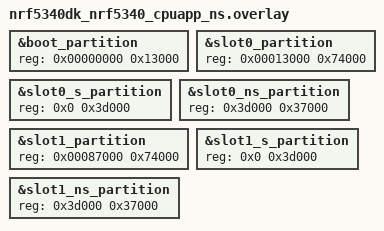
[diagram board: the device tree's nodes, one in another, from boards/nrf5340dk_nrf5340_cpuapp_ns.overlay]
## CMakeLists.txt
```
# SPDX-License-Identifier: Apache-2.0

cmake_minimum_required(VERSION 3.20.0)

find_package(Zephyr REQUIRED HINTS $ENV{ZEPHYR_BASE})
project(devacademy)

# STEP 6.1 - Include common files from Zephyr USB samples
target_sources(app PRIVATE src/main.c)
```

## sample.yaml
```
sample:
  description: nRF Connect SDK Intermediate Course by Nordic Developer Academy (https://academy.nordicsemi.com/)
  name: nRF Connect SDK Intermediate Course - Lesson 9 Exercise 4
  
common: 
    sysbuild: true
    build_only: true
    skip: true
    integration_platforms: 
      - nrf52833dk/nrf52833
      - nrf52840dk/nrf52840
      - nrf5340dk/nrf5340/cpuapp
      - nrf54lm20dk/nrf54lm20a/cpuapp
    platform_allow:
      - nrf52833dk/nrf52833
      - nrf52840dk/nrf52840
      - nrf5340dk/nrf5340/cpuapp
      - nrf54lm20dk/nrf54lm20a/cpuapp
    
tests:
  ncs_inter.l9.e4: {}
```

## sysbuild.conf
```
# Add MCUboot
SB_CONFIG_BOOTLOADER_MCUBOOT=y
SB_CONFIG_MCUBOOT_USE_ALL_AVAILABLE_RAM=y
```

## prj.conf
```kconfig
CONFIG_GPIO=y

# Enable MCUboot
CONFIG_BOOTLOADER_MCUBOOT=y

# Enable mcumgr DFU in application
CONFIG_MCUMGR=y

# Enable MCUMGR management for both OS and Images
CONFIG_MCUMGR_GRP_OS=y
CONFIG_MCUMGR_GRP_IMG=y

# Configure MCUMGR transport to UART
CONFIG_MCUMGR_TRANSPORT_UART=y

# Dependencies
# Configure dependencies for CONFIG_MCUMGR  
CONFIG_NET_BUF=y
CONFIG_ZCBOR=y
CONFIG_CRC=y

# Configure dependencies for CONFIG_MCUMGR_GRP_IMG  
CONFIG_FLASH=y
CONFIG_IMG_MANAGER=y

# Configure dependencies for CONFIG_IMG_MANAGER  
CONFIG_STREAM_FLASH=y
CONFIG_FLASH_MAP=y

# Configure dependencies for CONFIG_MCUMGR_TRANSPORT_UART 
CONFIG_BASE64=y

# STEP 5.3 - Enable USB subsystem
```

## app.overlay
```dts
/* STEP 5.1 - choose CDC ACM for mcumgr */

/* STEP 5.2 - Configure CDC ACM */
```

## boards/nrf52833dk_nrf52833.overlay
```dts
/delete-node/ &slot1_partition;
/delete-node/ &slot0_partition;
/delete-node/ &storage_partition;

&flash0 {
	partitions {
		ranges;
		#address-cells = <1>;
		#size-cells = <1>;

		boot_partition: partition@0 {
			compatible = "zephyr,mapped-partition";
			label = "mcuboot";
			reg = <0x00000000 0x13000>;
		};

		slot0_partition: partition@13000 {
			compatible = "zephyr,mapped-partition";
			label = "image-0";
			reg = <0x00013000 0x17000>;
		};

		slot1_partition: partition@2a000 {
			compatible = "zephyr,mapped-partition";
			label = "image-1";
			reg = <0x0002a000 0x17000>;
		};

		storage_partition: partition@41000 {
			compatible = "zephyr,mapped-partition";
			label = "storage";
			reg = <0x00041000 0x00006000>;
		};
	};
};

/* STEP 5.1 - Configure CDC ACM */
/* STEP 5.2 - Choose CDC ACM for mcumgr */
```

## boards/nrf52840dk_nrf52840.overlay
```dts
/delete-node/ &slot1_partition;
/delete-node/ &slot0_partition;
/delete-node/ &storage_partition;

&flash0 {
	partitions {
		ranges;
		#address-cells = <1>;
		#size-cells = <1>;

		boot_partition: partition@0 {
			compatible = "zephyr,mapped-partition";
			label = "mcuboot";
			reg = <0x00000000 0x00013000>;
		};

		slot0_partition: partition@13000 {
			compatible = "zephyr,mapped-partition";
			label = "image-0";
			reg = <0x00013000 0x00076000>;
		};

		slot1_partition: partition@89000 {
			compatible = "zephyr,mapped-partition";
			label = "image-1";
			reg = <0x00089000 0x00076000>;
		};

		/*
		 * The flash starting at 0x000f8000 and ending at
		 * 0x000fffff is reserved for use by the application.
		 */

		/*
		 * Storage partition will be used by FCB/LittleFS/NVS
		 * if enabled.
		 */
		storage_partition: partition@ff000 {
			compatible = "zephyr,mapped-partition";
			label = "storage";
			reg = <0x000ff000 0x00001000>;
		};
	};
};

/* STEP 5.1 - Configure CDC ACM */
/* STEP 5.2 - Choose CDC ACM for mcumgr */
```

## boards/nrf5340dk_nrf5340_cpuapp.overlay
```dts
/delete-node/ &slot1_partition;
/delete-node/ &slot0_partition;
/delete-node/ &storage_partition;

&flash0 {
	partitions {
		ranges;
		#address-cells = <1>;
		#size-cells = <1>;

		boot_partition: partition@0 {
			compatible = "zephyr,mapped-partition";
			label = "mcuboot";
			reg = <0x00000000 0x13000>;
		};

		slot0_partition: partition@13000 {
			compatible = "zephyr,mapped-partition";
			label = "image-0";
			reg = <0x00013000 0x74000>;
		};

		slot1_partition: partition@87000 {
			compatible = "zephyr,mapped-partition";
			label = "image-1";
			reg = <0x00087000 0x74000>;
		};
	};
};

/* STEP 5.1 - Configure CDC ACM */
/* STEP 5.2 - Choose CDC ACM for mcumgr */
```

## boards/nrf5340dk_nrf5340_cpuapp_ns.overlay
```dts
/delete-node/ &storage_partition;

&boot_partition {
	reg = <0x00000000 0x13000>;
};

&slot0_partition {
	reg = <0x00013000 0x74000>;
	ranges = <0x0 0x13000 0x74000>;
};

&slot0_s_partition {
	reg = <0x0 0x3d000>;
};

&slot0_ns_partition {
	reg = <0x3d000 0x37000>;
};

&slot1_partition {
	reg = <0x00087000 0x74000>;
	ranges = <0x0 0x87000 0x74000>;
};

&slot1_s_partition {
	reg = <0x0 0x3d000>;
};

&slot1_ns_partition {
	reg = <0x3d000 0x37000>;
};

/* STEP 5.1 - Configure CDC ACM */
/* STEP 5.2 - Choose CDC ACM for mcumgr */
```

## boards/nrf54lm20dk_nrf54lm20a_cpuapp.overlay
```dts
/delete-node/ &boot_partition;
/delete-node/ &slot0_partition;
/delete-node/ &slot1_partition;

&cpuapp_rram {
    partitions {
        boot_partition: partition@0 {
            compatible = "zephyr,mapped-partition";
            label = "mcuboot";
            reg = <0x0 DT_SIZE_K(100)>;
        };

        slot0_partition: partition@19000 {
            compatible = "zephyr,mapped-partition";
            label = "image-0";
            reg = <0x19000 DT_SIZE_K(800)>;
        };

        slot1_partition: partition@e1000 {
            compatible = "zephyr,mapped-partition";
            label = "image-1";
            reg = <0xe1000 DT_SIZE_K(800)>;
        };
    };
};
/* STEP 5.1 - Configure CDC ACM */
/* STEP 5.2 - Choose CDC ACM for mcumgr */
```

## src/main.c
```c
/*
 * Copyright (c) 2016 Intel Corporation
 *
 * SPDX-License-Identifier: Apache-2.0
 */

#include <zephyr/kernel.h>
#include <zephyr/drivers/gpio.h>

/* STEP 7.1 - Include header for usb */

/* 1000 msec = 1 sec */

#define SLEEP_TIME_MS   1000

/* The devicetree node identifier for the "led0" alias. */
#define LED0_NODE DT_ALIAS(led0)

/*
 * A build error on this line means your board is unsupported.
 * See the sample documentation for information on how to fix this.
 */
static const struct gpio_dt_spec led = GPIO_DT_SPEC_GET(LED0_NODE, gpios);

/* STEP 7.2 - Create context for USB stack */
/* STEP 7.3 - Create VBUS callback function */

int main(void)
{
    int ret;

    /* STEP 7.4 - Initialize usb device */
    /* STEP 7.5 - Enable usb device in case vbus not detected */

    if (!device_is_ready(led.port)) {
        return 0;
    }

    ret = gpio_pin_configure_dt(&led, GPIO_OUTPUT_ACTIVE);
    if (ret < 0) {
        return 0;
    }

    while (1) {
        ret = gpio_pin_toggle_dt(&led);
        if (ret < 0) {
            return 0;
        }
        k_msleep(SLEEP_TIME_MS);
    }
  return 1;
}
```
